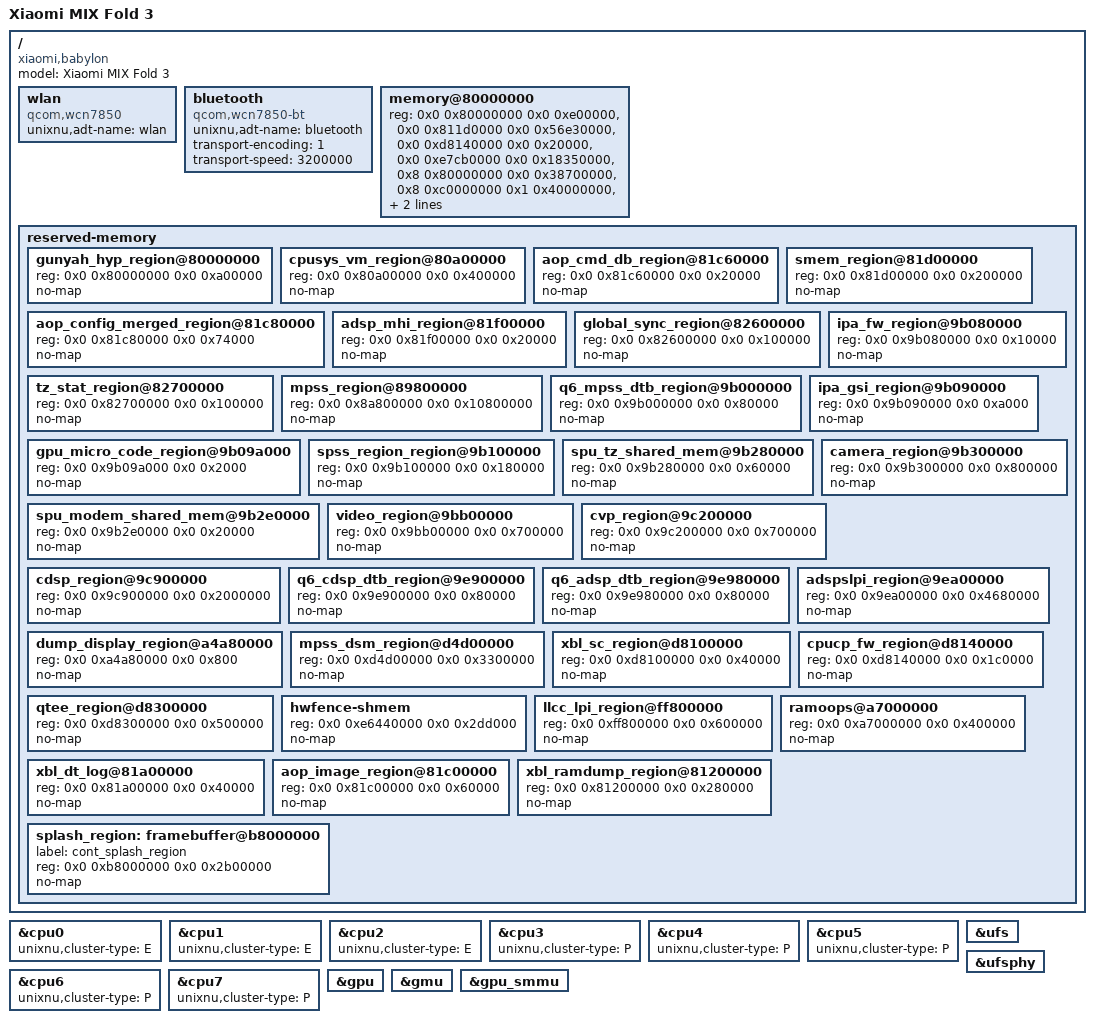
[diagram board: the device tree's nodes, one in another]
/dts-v1/;
/include/ "sm8550.dtsi"

// Generated from babylon live /sys/firmware/fdt (HyperOS 3.0.304.0, Android 16).
// Layout follows UniXNU-sheng dts/sheng.dts; reserved-memory follows UniXNU-zizhan gen_reserved.py approach.

/ {
    model = "Xiaomi MIX Fold 3";
    compatible = "xiaomi,babylon", "qcom,sm8550";

    wlan {
        compatible = "qcom,wcn7850";
        unixnu,adt-name = "wlan";
        status = "okay";
    };

    bluetooth {
        device_type = "bluetooth";
        compatible = "qcom,wcn7850-bt";
        unixnu,adt-name = "bluetooth";
        transport-encoding = <1>;
        transport-speed = <3200000>;
        status = "okay";
    };

    memory@80000000 {
        device_type = "memory";
        reg = <0x0 0x80000000 0x0 0xe00000>, <0x0 0x811d0000 0x0 0x56e30000>, <0x0 0xd8140000 0x0 0x20000>, <0x0 0xe7cb0000 0x0 0x18350000>, <0x8 0x80000000 0x0 0x38700000>, <0x8 0xc0000000 0x1 0x40000000>, <0xa 0x0 0x2 0x0>, <0x8 0xb8900000 0x0 0x1e00000>;
    };

    reserved-memory {
        #address-cells = <2>;
        #size-cells = <2>;
        ranges;
        gunyah_hyp_region@80000000 {
            reg = <0x0 0x80000000 0x0 0xa00000>;
            no-map;
        };
        cpusys_vm_region@80a00000 {
            reg = <0x0 0x80a00000 0x0 0x400000>;
            no-map;
        };
        aop_cmd_db_region@81c60000 {
            reg = <0x0 0x81c60000 0x0 0x20000>;
            no-map;
        };
        aop_config_merged_region@81c80000 {
            reg = <0x0 0x81c80000 0x0 0x74000>;
            no-map;
        };
        smem_region@81d00000 {
            reg = <0x0 0x81d00000 0x0 0x200000>;
            no-map;
        };
        adsp_mhi_region@81f00000 {
            reg = <0x0 0x81f00000 0x0 0x20000>;
            no-map;
        };
        global_sync_region@82600000 {
            reg = <0x0 0x82600000 0x0 0x100000>;
            no-map;
        };
        tz_stat_region@82700000 {
            reg = <0x0 0x82700000 0x0 0x100000>;
            no-map;
        };
        mpss_region@89800000 {
            reg = <0x0 0x8a800000 0x0 0x10800000>;
            no-map;
        };
        q6_mpss_dtb_region@9b000000 {
            reg = <0x0 0x9b000000 0x0 0x80000>;
            no-map;
        };
        ipa_fw_region@9b080000 {
            reg = <0x0 0x9b080000 0x0 0x10000>;
            no-map;
        };
        ipa_gsi_region@9b090000 {
            reg = <0x0 0x9b090000 0x0 0xa000>;
            no-map;
        };
        gpu_micro_code_region@9b09a000 {
            reg = <0x0 0x9b09a000 0x0 0x2000>;
            no-map;
        };
        spss_region_region@9b100000 {
            reg = <0x0 0x9b100000 0x0 0x180000>;
            no-map;
        };
        spu_tz_shared_mem@9b280000 {
            reg = <0x0 0x9b280000 0x0 0x60000>;
            no-map;
        };
        spu_modem_shared_mem@9b2e0000 {
            reg = <0x0 0x9b2e0000 0x0 0x20000>;
            no-map;
        };
        camera_region@9b300000 {
            reg = <0x0 0x9b300000 0x0 0x800000>;
            no-map;
        };
        video_region@9bb00000 {
            reg = <0x0 0x9bb00000 0x0 0x700000>;
            no-map;
        };
        cvp_region@9c200000 {
            reg = <0x0 0x9c200000 0x0 0x700000>;
            no-map;
        };
        cdsp_region@9c900000 {
            reg = <0x0 0x9c900000 0x0 0x2000000>;
            no-map;
        };
        q6_cdsp_dtb_region@9e900000 {
            reg = <0x0 0x9e900000 0x0 0x80000>;
            no-map;
        };
        q6_adsp_dtb_region@9e980000 {
            reg = <0x0 0x9e980000 0x0 0x80000>;
            no-map;
        };
        adspslpi_region@9ea00000 {
            reg = <0x0 0x9ea00000 0x0 0x4680000>;
            no-map;
        };
        dump_display_region@a4a80000 {
            reg = <0x0 0xa4a80000 0x0 0x800>;
            no-map;
        };
        mpss_dsm_region@d4d00000 {
            reg = <0x0 0xd4d00000 0x0 0x3300000>;
            no-map;
        };
        xbl_sc_region@d8100000 {
            reg = <0x0 0xd8100000 0x0 0x40000>;
            no-map;
        };
        cpucp_fw_region@d8140000 {
            reg = <0x0 0xd8140000 0x0 0x1c0000>;
            no-map;
        };
        qtee_region@d8300000 {
            reg = <0x0 0xd8300000 0x0 0x500000>;
            no-map;
        };
        hwfence-shmem {
            reg = <0x0 0xe6440000 0x0 0x2dd000>;
            no-map;
        };
        llcc_lpi_region@ff800000 {
            reg = <0x0 0xff800000 0x0 0x600000>;
            no-map;
        };
        ramoops@a7000000 {
            reg = <0x0 0xa7000000 0x0 0x400000>;
            no-map;
        };
        xbl_dt_log@81a00000 {
            reg = <0x0 0x81a00000 0x0 0x40000>;
            no-map;
        };
        aop_image_region@81c00000 {
            reg = <0x0 0x81c00000 0x0 0x60000>;
            no-map;
        };
        xbl_ramdump_region@81200000 {
            reg = <0x0 0x81200000 0x0 0x280000>;
            no-map;
        };
        splash_region: framebuffer@b8000000 {
            label = "cont_splash_region";
            reg = <0x0 0xb8000000 0x0 0x2b00000>;
            no-map;
        };
    };
};

// The scheduler runs the A510 cores as an E cluster and the others as a P cluster.
&cpu0 { unixnu,cluster-type = "E"; };
&cpu1 { unixnu,cluster-type = "E"; };
&cpu2 { unixnu,cluster-type = "E"; };
&cpu3 { unixnu,cluster-type = "P"; };
&cpu4 { unixnu,cluster-type = "P"; };
&cpu5 { unixnu,cluster-type = "P"; };
&cpu6 { unixnu,cluster-type = "P"; };
&cpu7 { unixnu,cluster-type = "P"; };
&ufs { status = "okay"; };
&ufsphy { status = "okay"; };
&gpu { status = "okay"; };
&gmu { status = "okay"; };
&gpu_smmu { status = "okay"; };
